# NANO100AN_v1 register map
File version: 1.0
Registers are 32-bit, read-write, reset 0x0 unless marked. A register's access mark holds for its fields unless they carry their own. Offsets are from the block's base; [hi:lo] are bit positions; {n}, {i} and the like mark numbered series.

## RTC — RTC Register Map
Base 0x40008000
0x00 RTC_INIR — RTC Initiation Register
  [31:0] INIR wo — RTC Initiation (Write Only). When RTC block is powered on, RTC is at reset state. User has to write a number (0x a5eb1357) to INIR to make RTC leaving reset state. Once the INIR is written as 0xa5eb1357, the RTC will be in un-reset state permanently. The INIR is a write-only field and read value will be always "0". RTC Active Status (Read Only),
    0=RTC is at reset state; 1=RTC is at normal active state
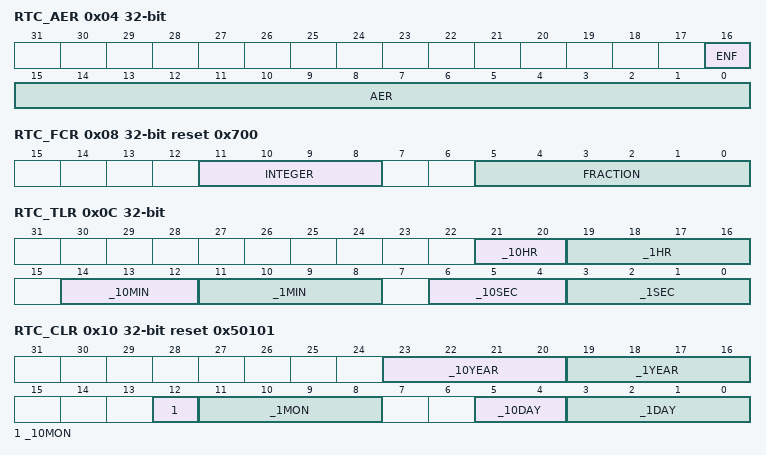
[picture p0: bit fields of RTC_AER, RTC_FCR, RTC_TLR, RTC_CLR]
0x04 RTC_AER — RTC Access Enable Register
  [16] ENF ro — RTC Register Access Enable Flag (Read Only)
    0=RTC register read/write disable; 1=RTC register read/write enable
  [15:0] AER wo — RTC Register Access Enable Password (Write Only)
    0xA965=Enable RTC acces.s
0x08 RTC_FCR reset 0x700 — RTC Frequency Compensation Register
  [11:8] INTEGER — Integer Part
  [5:0] FRACTION — Fraction Part. Note: Digit in FCR must be expressed as hexadecimal number.
0x0C RTC_TLR — Time Loading Register
  [21:20] _10HR — 10 Hour Time Digit (0~2)
  [19:16] _1HR — 1 Hour Time Digit (0~9)
  [14:12] _10MIN — 10 Min Time Digit (0~5)
  [11:8] _1MIN — 1 Min Time Digit (0~9)
  [6:4] _10SEC — 10 Sec Time Digit (0~5)
  [3:0] _1SEC — 1 Sec Time Digit (0~9)
0x10 RTC_CLR reset 0x50101 — Calendar Loading Register
  [23:20] _10YEAR — 10 Year Calendar Digit (0~9)
  [19:16] _1YEAR — 1 Year Calendar Digit (0~9)
  [12] _10MON — 10 Month Calendar Digit (0~1)
  [11:8] _1MON — 1 Month Calendar Digit (0~9)
  [5:4] _10DAY — 10 Day Calendar Digit (0~3)
  [3:0] _1DAY — 1 Day Calendar Digit (0~9)
0x14 RTC_TSSR reset 0x1 — Time Scale Selection Register
  [0] _24hr_12hr — 24-Hour / 12-Hour Mode Selection
    0=select 12-hour time scale with AM and PM indication; 1=select 24-hour time scale
0x18 RTC_DWR reset 0x6 — Day of the Week Register
  [2:0] DWR — Day Of The Week Register
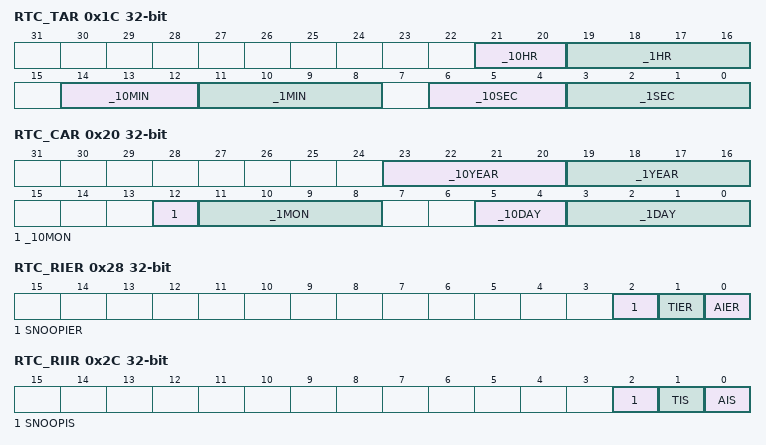
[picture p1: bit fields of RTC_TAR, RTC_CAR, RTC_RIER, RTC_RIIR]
0x1C RTC_TAR — Time Alarm Register
  [21:20] _10HR — 10 Hour Time Digit of Alarm Setting (0~2)
  [19:16] _1HR — 1 Hour Time Digit of Alarm Setting (0~9)
  [14:12] _10MIN — 10 Min Time Digit of Alarm Setting (0~5)
  [11:8] _1MIN — 1 Min Time Digit of Alarm Setting (0~9)
  [6:4] _10SEC — 10 Sec Time Digit of Alarm Setting (0~5)
  [3:0] _1SEC — 1 Sec Time Digit of Alarm Setting (0~9)
0x20 RTC_CAR — Calendar Alarm Register
  [23:20] _10YEAR — 10 Year Calendar Digit of Alarm Setting (0~9)
  [19:16] _1YEAR — 1 Year Calendar Digit of Alarm Setting (0~9)
  [12] _10MON — 10 Month Calendar Digit of Alarm Setting (0~1)
  [11:8] _1MON — 1 Month Calendar Digit of Alarm Setting (0~9)
  [5:4] _10DAY — 10 Day Calendar Digit of Alarm Setting (0~3)
  [3:0] _1DAY — 1 Day Calendar Digit of Alarm Setting (0~9)
0x24 RTC_LIR ro — RTC Leap Year Indication Register
  [0] LIR — Leap Year Indication REGISTER (Read Only)
    0=This year is not a leap year; 1=This year is leap year
0x28 RTC_RIER — RTC Interrupt Enable Register
  [2] SNOOPIER — Snooper Pin Event Detection Interrupt Enable
    0=Snooper Pin Event Detection Interrupt is disabled; 1=Snooper Pin Event Detection Interrupt is enabled
  [1] TIER — Time Tick Interrupt And Wake-Up By Tick Enable
    0=RTC Time Tick Interrupt is disabled; 1=RTC Time Tick Interrupt is enabled
  [0] AIER — Alarm Interrupt Enable
    0=RTC Alarm Interrupt is disabled; 1=RTC Alarm Interrupt is enabled
0x2C RTC_RIIR — RTC Interrupt Indicator Register
  [2] SNOOPIS — Snooper Pin Event Detection Interrupt Status. When SNOOPEN is high and an event defined by SNOOPEDGE detected in snooper pin, this flag will be set. While this bit is set and SNOOPIER is also high, RTC will generate an interrupt to CPU. Write "1" to clear this bit to "0".
    0=Snooper pin event defined by SNOOPEDGE never detected; 1=Snooper pin event defined by SNOOPEDGE detected
  [1] TIS — RTC Time Tick Interrupt Status. RTC unit will set TIF to high periodically in the period selected by TTR(RTC_TTR[2:0]). When this bit is set and TIER is also high, RTC will generate an interrupt to CPU. This bit is software clear by writing "1" to it.
    0=Indicates RCT Time Tick Interrupt condition never occurred; 1=Indicates RTC Time Tick Interrupt is requested
  [0] AIS — RTC Alarm Interrupt Status. RTC unit will set AIF to high once the RTC real time counters TLR and CLR reach the alarm setting time registers TAR and CAR. When this bit is set and AIER is also high, RTC will generate an interrupt to CPU. This bit is software clear by writing "1" to it.
    0=Indicates RCT Alarm Interrupt condition never occurred; 1=Indicates RTC Alarm Interrupt is requested if RIER.AIER=1
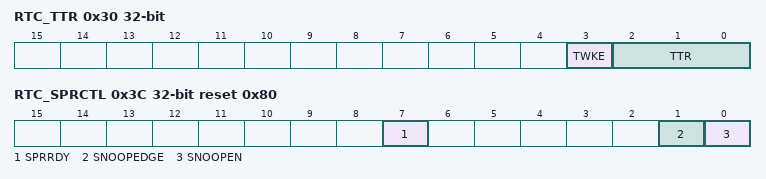
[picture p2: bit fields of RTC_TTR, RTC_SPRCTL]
0x30 RTC_TTR — RTC Time Tick Register
  [3] TWKE — RTC Timer Wake-Up CPU Function Enable Bit. If TWKE is set before CPU enters power-down mode, when a RTC Time Tick, CPU will be wakened up by RTC unit. Note: Tick timer setting follows the TTR description.
    0=Time Tick wake-up CPU function Disabled; 1=Wake-up function Enabled so that CPU can be waken up from Power-down mode by Time Tick
  [2:0] TTR — Time Tick Register
0x3C RTC_SPRCTL reset 0x80 — RTC Spare Functional Control Register
  [7] SPRRDY — SPR Register Ready. This bit indicates if the registers SPR0 ~ SPR19 are ready to read. After CPU writing registers SPR0 ~ SPR19, polling this bit to check if SP0 ~ SPR19 are updated done is necessary. This it is a read only bit and any write to this bit won't take any effect.
    0=SPR0 ~ SPR19 updating is in progress; 1=SPR0 ~ SPR19 are updated done and ready to read
  [1] SNOOPEDGE — Snooper Active Edge Selection. This bit defines which edge of snooper pin will generate a snooper pin detected event to clear the 20 spare registers.
    0=Rising edge of snooper pin generates snooper pin detected event; 1=Falling edge of snooper pin generates snooper pin detected event
  [0] SNOOPEN — Snooper Pin Event Detection Enable. This bit enables the snooper pin event detection. When this bit is set high and an event defined by SNOOPEDGE detected, the 20 spare registers will be cleared to "0" by hardware automatically. And, the SNOOPIF will also be set. In addition, RTC will also generate wake-up event to wake system up.
    0=Snooper pin event detection function Disabled; 1=Snooper pin event detection function Enabled
{0x40+4i} RTC_SPR{i} (i=0..19) — RTC Spare Register {i}
  [31:0] SPARE — SPARE. This field is used to store back-up information defined by software. This field will be cleared by hardware automatically once a snooper pin event is detected.
